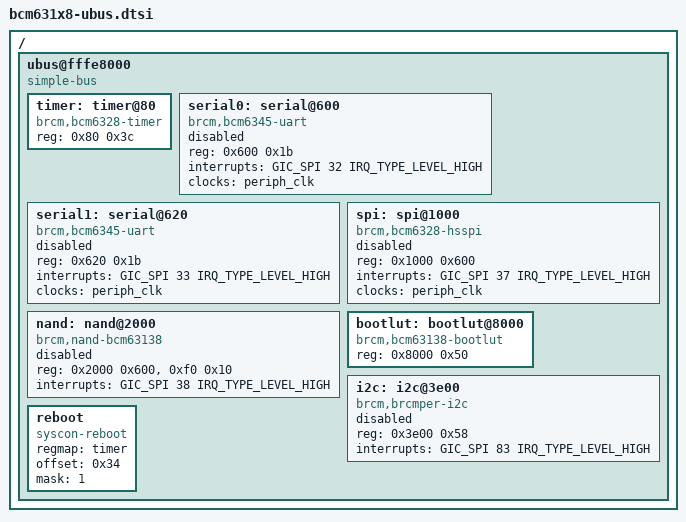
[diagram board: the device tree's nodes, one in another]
// SPDX-License-Identifier: GPL-2.0
/*
 * Broadcom BCM631x8 DSL SoCs UBUS peripherals DTSI
 */
#include "skeleton.dtsi"

/ {
	/* Legacy UBUS base */
	ubus@fffe8000 {
		compatible = "simple-bus";
		#address-cells = <1>;
		#size-cells = <1>;
		ranges = <0 0xfffe8000 0x8100>;

		timer: timer@80 {
			compatible = "brcm,bcm6328-timer", "syscon";
			reg = <0x80 0x3c>;
		};

		serial0: serial@600 {
			compatible = "brcm,bcm6345-uart";
			reg = <0x600 0x1b>;
			interrupts = <GIC_SPI 32 IRQ_TYPE_LEVEL_HIGH>;
			clocks = <&periph_clk>;
			clock-names = "periph";
			status = "disabled";
		};

		serial1: serial@620 {
			compatible = "brcm,bcm6345-uart";
			reg = <0x620 0x1b>;
			interrupts = <GIC_SPI 33 IRQ_TYPE_LEVEL_HIGH>;
			clocks = <&periph_clk>;
			clock-names = "periph";
			status = "disabled";
		};

		spi: spi@1000 {
			compatible = "brcm,bcm6328-hsspi";
			reg = <0x1000 0x600>;
			interrupts = <GIC_SPI 37 IRQ_TYPE_LEVEL_HIGH>;
			clocks = <&periph_clk>;
			clock-names = "hsspi";
			status = "disabled";
		};

		nand: nand@2000 {
			#address-cells = <1>;
			#size-cells = <0>;
			compatible = "brcm,nand-bcm63138", "brcm,brcmnand-v7.0", "brcm,brcmnand";
			reg = <0x2000 0x600>, <0xf0 0x10>;
			reg-names = "nand", "nand-int-base";
			status = "disabled";
			interrupts = <GIC_SPI 38 IRQ_TYPE_LEVEL_HIGH>;
			interrupt-names = "nand";
		};

		bootlut: bootlut@8000 {
			compatible = "brcm,bcm63138-bootlut",
				     "syscon";
			reg = <0x8000 0x50>;
		};

		i2c: i2c@3e00 {
			compatible = "brcm,brcmper-i2c";
			reg = <0x3e00 0x58>;
			interrupts= <GIC_SPI 83 IRQ_TYPE_LEVEL_HIGH>;
			#address-cells = <1>;
			#size-cells = <0>;
			status = "disabled";
		};

		reboot {
			compatible = "syscon-reboot";
			regmap = <&timer>;
			offset = <0x34>;
			mask = <1>;
		};
	};
};
